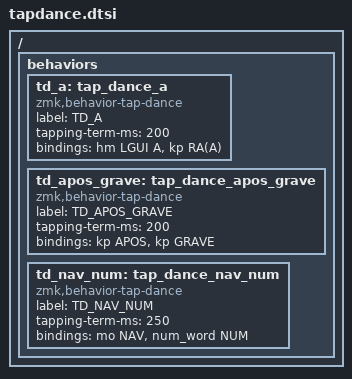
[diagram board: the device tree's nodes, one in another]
/ {
    behaviors {

        td_a: tap_dance_a {
            compatible = "zmk,behavior-tap-dance";
            label = "TD_A";
            #binding-cells = <0>;
            tapping-term-ms = <200>;
            bindings = <&hm LGUI A>, <&kp RA(A)>;
        };

        td_apos_grave: tap_dance_apos_grave {
            compatible = "zmk,behavior-tap-dance";
            label = "TD_APOS_GRAVE";
            #binding-cells = <0>;
            tapping-term-ms = <200>;
            bindings = <&kp APOS>, <&kp GRAVE>;
        };

        td_nav_num: tap_dance_nav_num {
            compatible = "zmk,behavior-tap-dance";
            label = "TD_NAV_NUM";
            #binding-cells = <0>;
            tapping-term-ms = <250>;
            bindings = <&mo NAV>, <&num_word NUM>;
        };

    };
};
